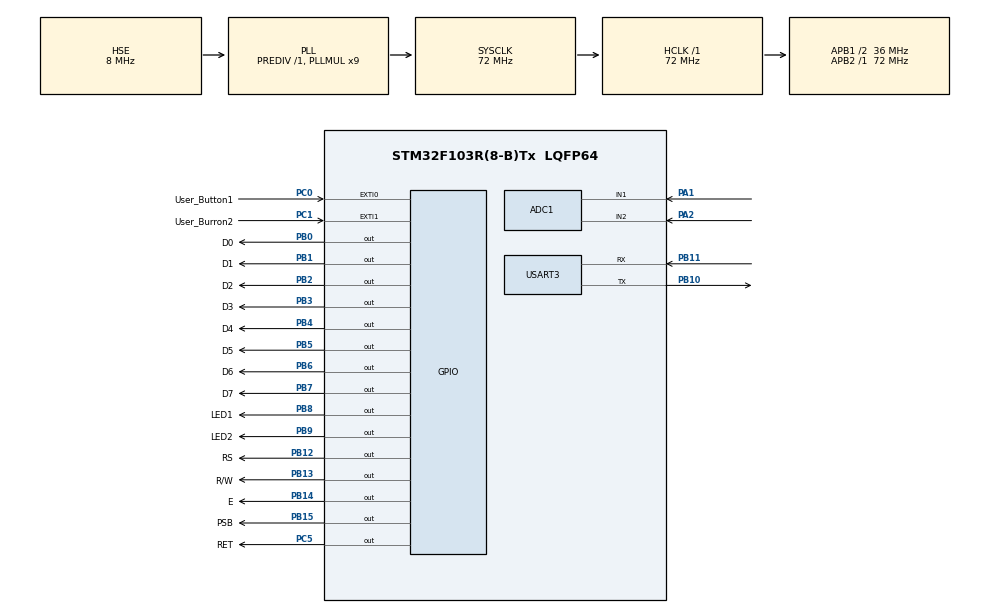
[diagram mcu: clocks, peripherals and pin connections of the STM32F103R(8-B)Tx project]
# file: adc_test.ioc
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ADC1.Channel-0\#ChannelRegularConversion=ADC_CHANNEL_2
ADC1.Channel-1\#ChannelRegularConversion=ADC_CHANNEL_1
ADC1.ContinuousConvMode=ENABLE
ADC1.EnableInjectedConversion=DISABLE
ADC1.InjNumberOfConversion=0
ADC1.NbrOfConversion=2
ADC1.NbrOfConversionFlag=1
ADC1.Rank-0\#ChannelRegularConversion=1
ADC1.Rank-1\#ChannelRegularConversion=2
ADC1.SamplingTime-0\#ChannelRegularConversion=ADC_SAMPLETIME_55CYCLES_5
ADC1.SamplingTime-1\#ChannelRegularConversion=ADC_SAMPLETIME_55CYCLES_5
ADC1.master=1
Dma.ADC1.0.Direction=DMA_PERIPH_TO_MEMORY
Dma.ADC1.0.Instance=DMA1_Channel1
Dma.ADC1.0.MemDataAlignment=DMA_MDATAALIGN_WORD
Dma.ADC1.0.MemInc=DMA_MINC_ENABLE
Dma.ADC1.0.Mode=DMA_CIRCULAR
Dma.ADC1.0.PeriphDataAlignment=DMA_PDATAALIGN_WORD
Dma.ADC1.0.PeriphInc=DMA_PINC_DISABLE
Dma.ADC1.0.Priority=DMA_PRIORITY_LOW
Dma.Request0=ADC1
FREERTOS.Queues01=myQueue01,16,uint16_t,0,Dynamic,NULL,NULL
FREERTOS.Tasks01=defaultTask,24,128,StartDefaultTask,Default,NULL,Dynamic,NULL,NULL;myTask02,49,128,StartTask02,Default,NULL,Dynamic,NULL,NULL;myTask03,10,128,StartTask03,Default,NULL,Dynamic,NULL,NULL;myTask04,8,128,StartTask04,Default,NULL,Dynamic,NULL,NULL
Mcu.Family=STM32F1
Mcu.Name=STM32F103R(8-B)Tx
Mcu.Package=LQFP64
NVIC.ADC1_2_IRQn=true\:0\:0\:false\:false\:true\:false\:true\:true
NVIC.DMA1_Channel1_IRQn=true\:0\:0\:false\:false\:true\:true\:false\:true
NVIC.PriorityGroup=NVIC_PRIORITYGROUP_4
NVIC.TIM4_IRQn=true\:0\:0\:false\:false\:true\:false\:false\:true
NVIC.TimeBase=TIM4_IRQn
NVIC.TimeBaseIP=TIM4
PA1.Signal=ADCx_IN1
PA13.Mode=Serial_Wire
PA13.Signal=SYS_JTMS-SWDIO
PA14.Mode=Serial_Wire
PA14.Signal=SYS_JTCK-SWCLK
PA2.Signal=ADCx_IN2
PB0.GPIO_Label=D0
PB0.Signal=GPIO_Output
PB1.GPIO_Label=D1
PB1.Signal=GPIO_Output
PB10.Mode=Asynchronous
PB10.Signal=USART3_TX
PB11.Mode=Asynchronous
PB11.Signal=USART3_RX
PB12.GPIO_Label=RS
PB12.Signal=GPIO_Output
PB13.GPIO_Label=R/W
PB13.Signal=GPIO_Output
PB14.GPIO_Label=E
PB14.Signal=GPIO_Output
PB15.GPIO_Label=PSB
PB15.GPIO_PuPd=GPIO_PULLUP
PB15.PinState=GPIO_PIN_SET
PB15.Signal=GPIO_Output
PB2.GPIO_Label=D2
PB2.Signal=GPIO_Output
PB3.GPIO_Label=D3
PB3.Signal=GPIO_Output
PB4.GPIO_Label=D4
PB4.Signal=GPIO_Output
PB5.GPIO_Label=D5
PB5.Signal=GPIO_Output
PB6.GPIO_Label=D6
PB6.Signal=GPIO_Output
PB7.GPIO_Label=D7
PB7.Signal=GPIO_Output
PB8.GPIO_Label=LED1
PB8.Signal=GPIO_Output
PB9.GPIO_Label=LED2
PB9.Signal=GPIO_Output
PC0.GPIO_Label=User_Button1
PC0.GPIO_ModeDefaultEXTI=GPIO_MODE_IT_FALLING
PC0.GPIO_PuPd=GPIO_PULLUP
PC0.Signal=GPXTI0
PC1.GPIO_Label=User_Burron2
PC1.GPIO_ModeDefaultEXTI=GPIO_MODE_IT_FALLING
PC1.GPIO_PuPd=GPIO_PULLUP
PC1.Signal=GPXTI1
PC14-OSC32_IN.Mode=LSE-External-Oscillator
PC14-OSC32_IN.Signal=RCC_OSC32_IN
PC15-OSC32_OUT.Mode=LSE-External-Oscillator
PC15-OSC32_OUT.Signal=RCC_OSC32_OUT
PC5.GPIO_Label=RET
PC5.GPIO_PuPd=GPIO_PULLUP
PC5.PinState=GPIO_PIN_SET
PC5.Signal=GPIO_Output
PD0-OSC_IN.Mode=HSE-External-Oscillator
PD0-OSC_IN.Signal=RCC_OSC_IN
PD1-OSC_OUT.Mode=HSE-External-Oscillator
PD1-OSC_OUT.Signal=RCC_OSC_OUT
ProjectManager.HeapSize=0x200
ProjectManager.StackSize=0x400
ProjectManager.TargetToolchain=MDK-ARM V5.27
RCC.ADCPresc=RCC_ADCPCLK2_DIV6
RCC.AHBFreq_Value=72000000
RCC.APB1CLKDivider=RCC_HCLK_DIV2
RCC.APB1Freq_Value=36000000
RCC.APB1TimFreq_Value=72000000
RCC.APB2Freq_Value=72000000
RCC.APB2TimFreq_Value=72000000
RCC.HCLKFreq_Value=72000000
RCC.PLLMUL=RCC_PLL_MUL9
RCC.PLLSourceVirtual=RCC_PLLSOURCE_HSE
RCC.SYSCLKFreq_VALUE=72000000
RCC.SYSCLKSource=RCC_SYSCLKSOURCE_PLLCLK
RCC.USBFreq_Value=72000000
SH.ADCx_IN1.0=ADC1_IN1,IN1
SH.ADCx_IN2.0=ADC1_IN2,IN2
USART3.VirtualMode=VM_ASYNC
VP_FREERTOS_VS_CMSIS_V2.Mode=CMSIS_V2
VP_SYS_VS_tim4.Mode=TIM4
board=custom

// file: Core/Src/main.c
/* USER CODE BEGIN Header */
/**
  ******************************************************************************
  * @file           : main.c
  * @brief          : Main program body
  ******************************************************************************
  * @attention
  *
  * <h2><center>&copy; Copyright (c) 2020 STMicroelectronics.
  * All rights reserved.</center></h2>
  *
  * This software component is licensed by ST under BSD 3-Clause license,
  * the "License"; You may not use this file except in compliance with the
  * License. You may obtain a copy of the License at:
  *                        opensource.org/licenses/BSD-3-Clause
  *
  ******************************************************************************
  */
/* USER CODE END Header */
#include "main.h"
#include "cmsis_os.h"

ADC_HandleTypeDef hadc1;
DMA_HandleTypeDef hdma_adc1;

UART_HandleTypeDef huart3;

/* Definitions for defaultTask */
osThreadId_t defaultTaskHandle;
const osThreadAttr_t defaultTask_attributes = {
  .name = "defaultTask",
  .priority = (osPriority_t) osPriorityNormal,
  .stack_size = 128 * 4
};
/* Definitions for myTask02 */
osThreadId_t myTask02Handle;
const osThreadAttr_t myTask02_attributes = {
  .name = "myTask02",
  .priority = (osPriority_t) osPriorityRealtime1,
  .stack_size = 128 * 4
};
/* Definitions for myTask03 */
osThreadId_t myTask03Handle;
const osThreadAttr_t myTask03_attributes = {
  .name = "myTask03",
  .priority = (osPriority_t) osPriorityLow2,
  .stack_size = 128 * 4
};
/* Definitions for myTask04 */
osThreadId_t myTask04Handle;
const osThreadAttr_t myTask04_attributes = {
  .name = "myTask04",
  .priority = (osPriority_t) osPriorityLow,
  .stack_size = 128 * 4
};
/* Definitions for myQueue01 */
osMessageQueueId_t myQueue01Handle;
const osMessageQueueAttr_t myQueue01_attributes = {
  .name = "myQueue01"
};

void SystemClock_Config(void);
static void MX_GPIO_Init(void);
static void MX_DMA_Init(void);
static void MX_ADC1_Init(void);
static void MX_USART3_UART_Init(void);
void StartDefaultTask(void *argument);
void StartTask02(void *argument);
void StartTask03(void *argument);
void StartTask04(void *argument);

int main(void)
{

  /* MCU Configuration--------------------------------------------------------*/

  /* Reset of all peripherals, Initializes the Flash interface and the Systick. */
  HAL_Init();

  /* Configure the system clock */
  SystemClock_Config();

  /* Initialize all configured peripherals */
  MX_GPIO_Init();
  MX_DMA_Init();
  MX_ADC1_Init();
  MX_USART3_UART_Init();

  /* Init scheduler */
  osKernelInitialize();

  /* Create the queue(s) */
  /* creation of myQueue01 */
  myQueue01Handle = osMessageQueueNew (16, sizeof(uint16_t), &myQueue01_attributes);

  /* Create the thread(s) */
  /* creation of defaultTask */
  defaultTaskHandle = osThreadNew(StartDefaultTask, NULL, &defaultTask_attributes);

  /* creation of myTask02 */
  myTask02Handle = osThreadNew(StartTask02, NULL, &myTask02_attributes);

  /* creation of myTask03 */
  myTask03Handle = osThreadNew(StartTask03, NULL, &myTask03_attributes);

  /* creation of myTask04 */
  myTask04Handle = osThreadNew(StartTask04, NULL, &myTask04_attributes);

  /* Start scheduler */
  osKernelStart();

  /* We should never get here as control is now taken by the scheduler */
  /* Infinite loop */
  while (1)
  {

  }
}

void SystemClock_Config(void)
{
  RCC_OscInitTypeDef RCC_OscInitStruct = {0};
  RCC_ClkInitTypeDef RCC_ClkInitStruct = {0};
  RCC_PeriphCLKInitTypeDef PeriphClkInit = {0};

  /** Initializes the RCC Oscillators according to the specified parameters
  * in the RCC_OscInitTypeDef structure.
  */
  RCC_OscInitStruct.OscillatorType = RCC_OSCILLATORTYPE_HSE;
  RCC_OscInitStruct.HSEState = RCC_HSE_ON;
  RCC_OscInitStruct.HSEPredivValue = RCC_HSE_PREDIV_DIV1;
  RCC_OscInitStruct.HSIState = RCC_HSI_ON;
  RCC_OscInitStruct.PLL.PLLState = RCC_PLL_ON;
  RCC_OscInitStruct.PLL.PLLSource = RCC_PLLSOURCE_HSE;
  RCC_OscInitStruct.PLL.PLLMUL = RCC_PLL_MUL9;
  if (HAL_RCC_OscConfig(&RCC_OscInitStruct) != HAL_OK)
  {
    Error_Handler();
  }
  /** Initializes the CPU, AHB and APB buses clocks
  */
  RCC_ClkInitStruct.ClockType = RCC_CLOCKTYPE_HCLK|RCC_CLOCKTYPE_SYSCLK
                              |RCC_CLOCKTYPE_PCLK1|RCC_CLOCKTYPE_PCLK2;
  RCC_ClkInitStruct.SYSCLKSource = RCC_SYSCLKSOURCE_PLLCLK;
  RCC_ClkInitStruct.AHBCLKDivider = RCC_SYSCLK_DIV1;
  RCC_ClkInitStruct.APB1CLKDivider = RCC_HCLK_DIV2;
  RCC_ClkInitStruct.APB2CLKDivider = RCC_HCLK_DIV1;

  if (HAL_RCC_ClockConfig(&RCC_ClkInitStruct, FLASH_LATENCY_2) != HAL_OK)
  {
    Error_Handler();
  }
  PeriphClkInit.PeriphClockSelection = RCC_PERIPHCLK_ADC;
  PeriphClkInit.AdcClockSelection = RCC_ADCPCLK2_DIV6;
  if (HAL_RCCEx_PeriphCLKConfig(&PeriphClkInit) != HAL_OK)
  {
    Error_Handler();
  }
}

static void MX_ADC1_Init(void)
{

  ADC_ChannelConfTypeDef sConfig = {0};

  /** Common config
  */
  hadc1.Instance = ADC1;
  hadc1.Init.ScanConvMode = ADC_SCAN_ENABLE;
  hadc1.Init.ContinuousConvMode = ENABLE;
  hadc1.Init.DiscontinuousConvMode = DISABLE;
  hadc1.Init.ExternalTrigConv = ADC_SOFTWARE_START;
  hadc1.Init.DataAlign = ADC_DATAALIGN_RIGHT;
  hadc1.Init.NbrOfConversion = 2;
  if (HAL_ADC_Init(&hadc1) != HAL_OK)
  {
    Error_Handler();
  }
  /** Configure Regular Channel
  */
  sConfig.Channel = ADC_CHANNEL_2;
  sConfig.Rank = ADC_REGULAR_RANK_1;
  sConfig.SamplingTime = ADC_SAMPLETIME_55CYCLES_5;
  if (HAL_ADC_ConfigChannel(&hadc1, &sConfig) != HAL_OK)
  {
    Error_Handler();
  }
  /** Configure Regular Channel
  */
  sConfig.Channel = ADC_CHANNEL_1;
  sConfig.Rank = ADC_REGULAR_RANK_2;
  if (HAL_ADC_ConfigChannel(&hadc1, &sConfig) != HAL_OK)
  {
    Error_Handler();
  }

}

static void MX_USART3_UART_Init(void)
{

  huart3.Instance = USART3;
  huart3.Init.BaudRate = 115200;
  huart3.Init.WordLength = UART_WORDLENGTH_8B;
  huart3.Init.StopBits = UART_STOPBITS_1;
  huart3.Init.Parity = UART_PARITY_NONE;
  huart3.Init.Mode = UART_MODE_TX_RX;
  huart3.Init.HwFlowCtl = UART_HWCONTROL_NONE;
  huart3.Init.OverSampling = UART_OVERSAMPLING_16;
  if (HAL_UART_Init(&huart3) != HAL_OK)
  {
    Error_Handler();
  }

}

static void MX_DMA_Init(void)
{

  /* DMA controller clock enable */
  __HAL_RCC_DMA1_CLK_ENABLE();

  /* DMA interrupt init */
  /* DMA1_Channel1_IRQn interrupt configuration */
  HAL_NVIC_SetPriority(DMA1_Channel1_IRQn, 0, 0);
  HAL_NVIC_EnableIRQ(DMA1_Channel1_IRQn);

}

static void MX_GPIO_Init(void)
{
  GPIO_InitTypeDef GPIO_InitStruct = {0};

  /* GPIO Ports Clock Enable */
  __HAL_RCC_GPIOC_CLK_ENABLE();
  __HAL_RCC_GPIOD_CLK_ENABLE();
  __HAL_RCC_GPIOA_CLK_ENABLE();
  __HAL_RCC_GPIOB_CLK_ENABLE();

  /*Configure GPIO pin Output Level */
  HAL_GPIO_WritePin(RET_GPIO_Port, RET_Pin, GPIO_PIN_SET);

  /*Configure GPIO pin Output Level */
  HAL_GPIO_WritePin(GPIOB, D0_Pin|D1_Pin|D2_Pin|RS_Pin
                          |R_W_Pin|E_Pin|D3_Pin|D4_Pin
                          |D5_Pin|D6_Pin|D7_Pin|LED1_Pin
                          |LED2_Pin, GPIO_PIN_RESET);

  /*Configure GPIO pin Output Level */
  HAL_GPIO_WritePin(PSB_GPIO_Port, PSB_Pin, GPIO_PIN_SET);

  /*Configure GPIO pins : User_Button1_Pin User_Burron2_Pin */
  GPIO_InitStruct.Pin = User_Button1_Pin|User_Burron2_Pin;
  GPIO_InitStruct.Mode = GPIO_MODE_IT_FALLING;
  GPIO_InitStruct.Pull = GPIO_PULLUP;
  HAL_GPIO_Init(GPIOC, &GPIO_InitStruct);

  /*Configure GPIO pin : RET_Pin */
  GPIO_InitStruct.Pin = RET_Pin;
  GPIO_InitStruct.Mode = GPIO_MODE_OUTPUT_PP;
  GPIO_InitStruct.Pull = GPIO_PULLUP;
  GPIO_InitStruct.Speed = GPIO_SPEED_FREQ_LOW;
  HAL_GPIO_Init(RET_GPIO_Port, &GPIO_InitStruct);

  /*Configure GPIO pins : D0_Pin D1_Pin D2_Pin RS_Pin
                           R_W_Pin E_Pin D3_Pin D4_Pin
                           D5_Pin D6_Pin D7_Pin LED1_Pin
                           LED2_Pin */
  GPIO_InitStruct.Pin = D0_Pin|D1_Pin|D2_Pin|RS_Pin
                          |R_W_Pin|E_Pin|D3_Pin|D4_Pin
                          |D5_Pin|D6_Pin|D7_Pin|LED1_Pin
                          |LED2_Pin;
  GPIO_InitStruct.Mode = GPIO_MODE_OUTPUT_PP;
  GPIO_InitStruct.Pull = GPIO_NOPULL;
  GPIO_InitStruct.Speed = GPIO_SPEED_FREQ_LOW;
  HAL_GPIO_Init(GPIOB, &GPIO_InitStruct);

  /*Configure GPIO pin : PSB_Pin */
  GPIO_InitStruct.Pin = PSB_Pin;
  GPIO_InitStruct.Mode = GPIO_MODE_OUTPUT_PP;
  GPIO_InitStruct.Pull = GPIO_PULLUP;
  GPIO_InitStruct.Speed = GPIO_SPEED_FREQ_LOW;
  HAL_GPIO_Init(PSB_GPIO_Port, &GPIO_InitStruct);

}

void StartDefaultTask(void *argument)
{
  for(;;)
  {
    osDelay(1);
  }
}

void StartTask02(void *argument)
{
  /* USER CODE BEGIN StartTask02 */

	 uint32_t AD_DMA[2];
  float a,b;
  HAL_ADCEx_Calibration_Start(&hadc1);
  /* Infinite loop */

  for(;;)
  {
		HAL_ADC_Start_DMA(&hadc1,AD_DMA,2);
    a=AD_DMA[0];
		b=AD_DMA[1];
		printf("PA1电压为 %.2fV\r\n", (b * 3.3) / 4096);
		printf("PA2电压为 %.2fV\r\n", (a * 3.3) / 4096); // a除以4096 * 3.3 会更好理解

		printf("\r\n");

		osDelay(500);
  }
  /* USER CODE END StartTask02 */
}

void StartTask03(void *argument)
{
  /* USER CODE BEGIN StartTask03 */
  /* Infinite loop */
  for(;;)
  {
    printf("Task3 is runing!\n");
		osDelay(1000);
  }
  /* USER CODE END StartTask03 */
}

void StartTask04(void *argument)
{
  /* USER CODE BEGIN StartTask04 */
  /* Infinite loop */
  for(;;)
  {
    printf("Task4 is runing!\n");
		osDelay(1000);
  }
  /* USER CODE END StartTask04 */
}

void HAL_TIM_PeriodElapsedCallback(TIM_HandleTypeDef *htim)
{
  if (htim->Instance == TIM4) {
    HAL_IncTick();
  }
}

void Error_Handler(void)
{
}

/************************ (C) COPYRIGHT STMicroelectronics *****END OF FILE****/
